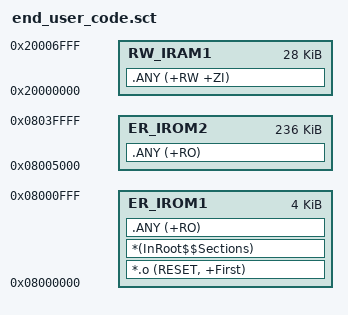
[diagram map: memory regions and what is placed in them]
; *************************************************************
; *** Scatter-Loading Description File generated by uVision ***
; *************************************************************

LR_IROM1 0x08000000 0x00001000  {    ; load region size_region
  ER_IROM1 0x08000000 0x00001000  {  ; load address = execution address
   *.o (RESET, +First)
   *(InRoot$$Sections)
   .ANY (+RO)
  }
  RW_IRAM1 0x20000000 0x00007000  {  ; RW data
   .ANY (+RW +ZI)
  }
  
 ; 0x20007000 ~ 0x20007FFF   RAM reserved for SLIB code
  
}

; 0x08001000 ~ 0x08002FFF is SLIB area 
; 0x08003000 ~ 0x08004FFF is used c lib
LR_IROM2 0x08005000 0x0003B000  {    ; load region size_region
  ER_IROM2 0x08005000 0x0003B000  {  ; load address = execution address
   .ANY (+RO)
  }
}



